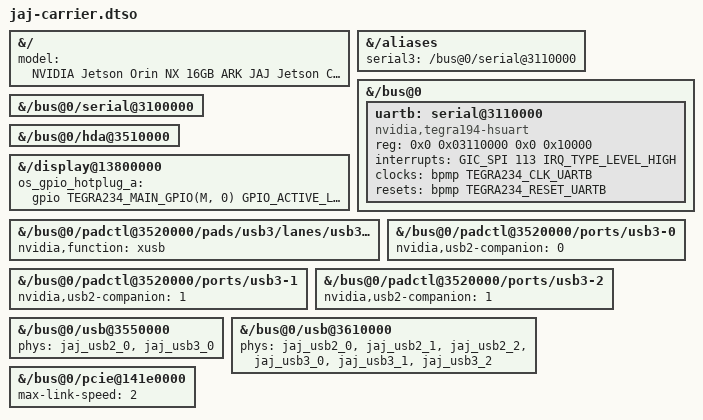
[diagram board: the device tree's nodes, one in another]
// SPDX-License-Identifier: GPL-2.0-only
/*
 * ARK Just A Jetson carrier changes, as an overlay on the stock
 * p3768-0000+p3767-0000 (Orin NX 16GB, Super) device tree.
 *
 * A port of ARK's src/ark/ark-JAJ-overrides.dtsi (ark_jetson_kernel, commit in
 * upstream.env), which ARK builds into a full device tree. Two of its changes
 * delete properties, which an overlay can't do:
 *
 *   - UART-A DMA: ARK deletes dmas/dma-names. Here dma-names is overwritten
 *     instead: serial-tegra takes PIO mode for any direction that has no "rx"
 *     or "tx" entry in dma-names (probe, of_property_match_string), which is
 *     the same end state.
 *   - hdcp_enabled on the display: not carried over. ARK drops it only to
 *     avoid a DP-to-HDMI adapter regression and notes that native HDMI, which
 *     the JAJ has, shouldn't hit it.
 *
 * Needs jaj-lane-labels.dtso applied first (the jaj_usb* labels).
 */

/dts-v1/;
/plugin/;

#include <dt-bindings/clock/tegra234-clock.h>
#include <dt-bindings/reset/tegra234-reset.h>
#include <dt-bindings/gpio/gpio.h>
#include <dt-bindings/gpio/tegra234-gpio.h>
#include <dt-bindings/interrupt-controller/arm-gic.h>

&{/} {
	model = "NVIDIA Jetson Orin NX 16GB ARK JAJ Jetson Carrier Super";
};

/* A literal path: &uartb would record this overlay's internal path. */
&{/aliases} {
	serial3 = "/bus@0/serial@3110000";
};

/* UART-B is wired on the carrier but undefined by the stock SoC tree. hsuart,
 * so it enumerates as /dev/ttyTHS3 like the other Tegra UARTs; no DMA (PIO). */
&{/bus@0} {
	uartb: serial@3110000 {
		compatible = "nvidia,tegra194-hsuart";
		reg = <0x0 0x03110000 0x0 0x10000>;
		interrupts = <GIC_SPI 113 IRQ_TYPE_LEVEL_HIGH>;
		clocks = <&bpmp TEGRA234_CLK_UARTB>;
		resets = <&bpmp TEGRA234_RESET_UARTB>;
		reset-names = "serial";
		status = "okay";
	};
};

/* UART-A: the stock gpcdma RX path corrupts the stream at 3 Mbaud. PIO. */
&{/bus@0/serial@3100000} {
	dma-names = "unused-rx", "unused-tx";
};

/* HD audio is used on the carrier. */
&{/bus@0/hda@3510000} {
	status = "okay";
};

/* HDMI display control block, and the hotplug line is active-low. */
&{/display@13800000} {
#include "jaj-hdmi-dcb.dtsi"
	os_gpio_hotplug_a = <&gpio TEGRA234_MAIN_GPIO(M, 0) GPIO_ACTIVE_LOW>;
};

/* Third USB 3 lane for the dual USB-A port. */
&{/bus@0/padctl@3520000/pads/usb3/lanes/usb3-2} {
	nvidia,function = "xusb";
	status = "okay";
};

/* Port mapping: usb3-0 = USB-C, usb3-1/usb3-2 = dual USB-A. */
&{/bus@0/padctl@3520000/ports/usb3-0} {
	nvidia,usb2-companion = <0>;
};
&{/bus@0/padctl@3520000/ports/usb3-1} {
	nvidia,usb2-companion = <1>;
	status = "okay";
};
&{/bus@0/padctl@3520000/ports/usb3-2} {
	nvidia,usb2-companion = <1>;
	status = "okay";
};

/* USB-C device controller (the recovery gadget) on the usb3-0 lane. */
&{/bus@0/usb@3550000} {
	phys = <&jaj_usb2_0>, <&jaj_usb3_0>;
	phy-names = "usb2-0", "usb3-0";
};

&{/bus@0/usb@3610000} {
	phys = <&jaj_usb2_0>, <&jaj_usb2_1>, <&jaj_usb2_2>,
	       <&jaj_usb3_0>, <&jaj_usb3_1>, <&jaj_usb3_2>;
	phy-names = "usb2-0", "usb2-1", "usb2-2",
		    "usb3-0", "usb3-1", "usb3-2";
};

/* C7 is the 16-pin PCIe FFC header: cap at 5 GT/s. */
&{/bus@0/pcie@141e0000} {
	max-link-speed = <2>;
};
